# PIC32MK1024GPD100 device description
Architecture: MIPS; Family: PIC32MK; Series: PIC32MK
Registers are 32-bit, read-write, no defined reset value unless marked. A register's access mark holds for its fields unless they carry their own. Offsets are from the block's base; [hi:lo] are bit positions; 'fields as' and 'values as' point back to an identical list.

## SPI
Instances: SPI 0x1f827000 in periph_pb2_std
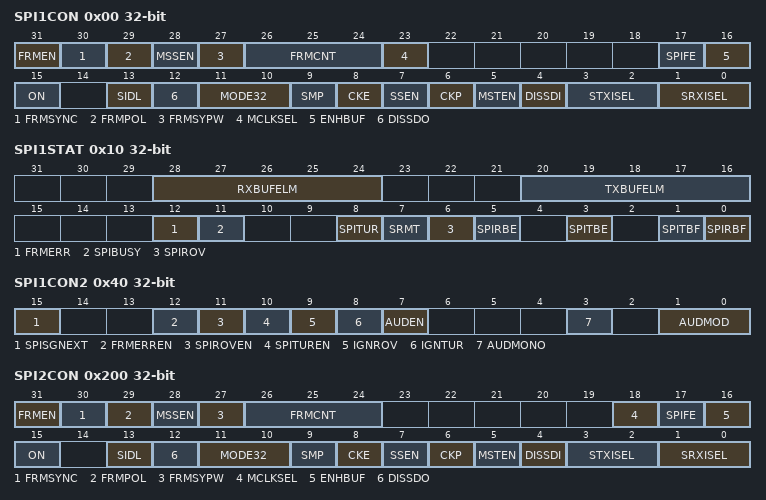
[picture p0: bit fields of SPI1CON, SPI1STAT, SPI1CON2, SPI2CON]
0x00 SPI1CON — SPI Control Register
  [31] FRMEN — Framed SPI Support bit
    1=Framed SPI support is enabled (SSx pin used as FSYNC input/output); 0=Framed SPI support is disabled
  [30] FRMSYNC — Frame Sync Pulse Direction Control on SSx pin bit
    1=Frame sync pulse input (Slave mode); 0=Frame sync pulse output (Master mode)
  [29] FRMPOL — Frame Sync Polarity bit
    1=Frame pulse is active-high; 0=Frame pulse is active-low
  [28] MSSEN — Master Mode Slave Select Enable bit
    1=Slave select SPI support enabled. The SS pin is automatically driven during transmission in Master mode. Polarity is determined by the FRMPOL bit.; 0=Slave select SPI support is disabled
  [27] FRMSYPW — Frame Sync Pulse Width bit
    1=Frame sync pulse is one character wide; 0=Frame sync pulse is one clock wide
  [26:24] FRMCNT — Frame Sync Pulse Counter bits. Controls the number of data characters transmitted per pulse. This bit is only valid in Framed mode.
    5=Generate a frame sync pulse on every 32 data characters; 4=Generate a frame sync pulse on every 16 data characters; 3=Generate a frame sync pulse on every 8 data characters; 2=Generate a frame sync pulse on every 4 data characters; 1=Generate a frame sync pulse on every 2 data characters; 0=Generate a frame sync pulse on every data character
  [23] MCLKSEL — Master Clock Enable bit
    1=REFCLKO1 is used by the Baud Rate Generator; 0=PBCLK2 is used by the Baud Rate Generator
  [17] SPIFE — Frame Sync Pulse Edge Select bit
    1=Frame synchronization pulse coincides with the first bit clock; 0=Frame synchronization pulse precedes the first bit clock
  [16] ENHBUF — Enhanced Buffer Enable bit
    1=Enhanced Buffer mode is enabled; 0=Enhanced Buffer mode is disabled
  [15] ON — SPI/I 2 S Module On bit
    1=SPI/I2S module is enabled; 0=SPI/I2S module is disabled
  [13] SIDL — Stop in Idle Mode bit
    1=Discontinue operation when CPU enters in Idle mode; 0=Continue operation in Idle mode
  [12] DISSDO — Disable SDOx pin bit
    1=SDOx pin is not used by the module. Pin is controlled by associated PORT register; 0=SDOx pin is controlled by the module
  [11:10] MODE32 — 32/16-Bit Communication Select bits
    3=SETTING1 ((AUDEN = 1) 24-bit Data, 32-bit FIFO, 32-bit Channel/64-bit Frame / (AUDEN = 0)32-bit); 2=SETTING2 ((AUDEN = 1) 32-bit Data, 32-bit FIFO, 32-bit Channel/64-bit Frame / (AUDEN = 0)32-bit); 1=SETTING3 ((AUDEN = 1) 16-bit Data, 16-bit FIFO, 32-bit Channel/64-bit Frame / (AUDEN = 0)16-bit); 0=SETTING4 ((AUDEN = 1) 16-bit Data, 16-bit FIFO, 16-bit Channel/32-bit Frame / (AUDEN = 0)8-bit)
  [9] SMP — SPI Data Input Sample Phase bit (master mode only)
    1=(Master mode) Input data sampled at end of data output time / (Slave mode) value is ignored; 0=(Master mode) Input data sampled at middle of data output time / (Slave mode) value is ignored
  [8] CKE — SPI Clock Edge Select bit
    1=Serial output data changes on transition from active clock state to Idle clock state (see CKP bit); 0=Serial output data changes on transition from Idle clock state to active clock state (see CKP bit)
  [7] SSEN — Slave Select Enable bit
    1=SSx pin used for Slave mode; 0=SSx pin not used for Slave mode
  [6] CKP — Clock Polarity Select bit
    1=Idle state for clock is a high level; active state is a low level; 0=Idle state for clock is a low level; active state is a high level
  [5] MSTEN — Master Mode Enable bit
    1=Master mode; 0=Slave mode
  [4] DISSDI — Disable SDI bit
    1=SDI pin is not used by the SPI module (pin is controlled by PORT function); 0=SDI pin is controlled by the SPI module
  [3:2] STXISEL — SPI Transmit Buffer Empty Interrupt Mode bits
    3=Interrupt is generated when the buffer is not full (has one or more empty elements); 2=Interrupt is generated when the buffer is empty by one-half or more; 1=Interrupt is generated when the buffer is completely empty; 0=Interrupt is generated when the last transfer is shifted out of SPISR and transmit operations are complete
  [1:0] SRXISEL — SPI Receive Buffer Full Interrupt Mode bits
    3=Interrupt is generated when the buffer is full; 2=Interrupt is generated when the buffer is full by one-half or more; 1=Interrupt is generated when the buffer is not empty; 0=Interrupt is generated when the last word in the receive buffer is read (i.e. buffer is empty)
0x10 SPI1STAT — SPI Status Register
  [28:24] RXBUFELM
  [20:16] TXBUFELM
  [12] FRMERR — SPI Frame Error status bit
    1=Frame error detected; 0=No Frame error detected
  [11] SPIBUSY — SPI Activity Status bit
    1=SPI peripheral is currently busy with some transactions; 0=SPI peripheral is currently idle
  [8] SPITUR — Transmit Under Run bit
    1=Transmit buffer has encountered an underrun condition; 0=Transmit buffer has no underrun condition
  [7] SRMT — Shift Register Empty bit
    1=When SPI module shift register is empty; 0=When SPI module shift register is not empty
  [6] SPIROV — Receive Overflow Flag bit
    1=A new data is completely received and discarded. The user software has not read the previous data in the SPIxBUF register.; 0=No overflow has occurred
  [5] SPIRBE — RX FIFO Empty bit (valid only when ENHBUF = 1)
    1=RX FIFO is empty (CRPTR = SWPTR); 0=RX FIFO is not empty (CRPTR ? SWPTR)
  [3] SPITBE — SPI Transmit Buffer Empty Status bit
    1=Transmit buffer; 0=Transmit buffer
  [1] SPITBF — SPI Transmit Buffer Full Status bit
    1=Transmit not yet started; 0=Transmit buffer is not full
  [0] SPIRBF — SPI Receive Buffer Full Status bit
    1=Receive buffer; 0=Receive buffer
0x20 SPI1BUF
0x30 SPI1BRG
  [12:0] SPI1BRG
0x40 SPI1CON2 — SPI Control Register 2
  [15] SPISGNEXT — Sign Extend Read Data from the RX FIFO bit
    1=Data from RX FIFO is sign extended; 0=Data from RX FIFO is not sign extened
  [12] FRMERREN — Enable Interrupt Events via FRMERR bit
    1=Frame Error overflow generates error events; 0=Frame Error does not generate error events
  [11] SPIROVEN — Enable Interrupt Events via SPIROV bit
    1=Receive overflow generates error events; 0=Receive overflow does not generate error events
  [10] SPITUREN — Enable Interrupt Events via SPITUR bit
    1=Transmit Underrun Generates Error Events; 0=Transmit Underrun Does Not Generates Error Events
  [9] IGNROV — Ignore Receive Overflow bit
    1=A ROV is not a critical error; during ROV data in the fifo is not overwritten by receive data; 0=A ROV is a critical error which stop SPI operation
  [8] IGNTUR — Ignore Transmit Underrun bit
    1=A TUR is not a critical error and zeros are transmitted until the SPIxTXB is not empty; 0=A TUR is a critical error which stop SPI operation
  [7] AUDEN — Enable Audio CODEC Support bit
    1=Audio protocol enabled; 0=Audio protocol disabled
  [3] AUDMONO — Transmit Audio Data Format bit
    1=Audio data is mono (Each data word is transmitted on both left and right channels); 0=Audio data is stereo
  [1:0] AUDMOD — Audio Protocol Mode bit
    3=PCM/DSP mode; 2=Right Justified mode; 1=Left Justified mode; 0=I2S mode
0x200 SPI2CON — SPI Control Register
  [31] FRMEN — Framed SPI Support bit
    values as SPI1CON.FRMEN
  [30] FRMSYNC — Frame Sync Pulse Direction Control on SSx pin bit
    values as SPI1CON.FRMSYNC
  [29] FRMPOL — Frame Sync Polarity bit
    1=Frame pulse is active-high; 0=Frame pulse is active-low
  [28] MSSEN — Master Mode Slave Select Enable bit
    values as SPI1CON.MSSEN
  [27] FRMSYPW — Frame Sync Pulse Width bit
    values as SPI1CON.FRMSYPW
  [26:24] FRMCNT — Frame Sync Pulse Counter bits. Controls the number of data characters transmitted per pulse. This bit is only valid in Framed mode.
    values as SPI1CON.FRMCNT
  [18] MCLKSEL — Master Clock Enable bit
    values as SPI1CON.MCLKSEL
  [17] SPIFE — Frame Sync Pulse Edge Select bit
    values as SPI1CON.SPIFE
  [16] ENHBUF — Enhanced Buffer Enable bit
    values as SPI1CON.ENHBUF
  [15] ON — SPI/I 2 S Module On bit
    1=SPI/I2S module is enabled; 0=SPI/I2S module is disabled
  [13] SIDL — Stop in Idle Mode bit
    values as SPI1CON.SIDL
  [12] DISSDO — Disable SDOx pin bit
    values as SPI1CON.DISSDO
  [11:10] MODE32 — 32/16-Bit Communication Select bits
    values as SPI1CON.MODE32
  [9] SMP — SPI Data Input Sample Phase bit (master mode only)
    values as SPI1CON.SMP
  [8] CKE — SPI Clock Edge Select bit
    values as SPI1CON.CKE
  [7] SSEN — Slave Select Enable bit
    values as SPI1CON.SSEN
  [6] CKP — Clock Polarity Select bit
    values as SPI1CON.CKP
  [5] MSTEN — Master Mode Enable bit
    1=Master mode; 0=Slave mode
  [4] DISSDI — Disable SDI bit
    values as SPI1CON.DISSDI
  [3:2] STXISEL — SPI Transmit Buffer Empty Interrupt Mode bits
    values as SPI1CON.STXISEL
  [1:0] SRXISEL — SPI Receive Buffer Full Interrupt Mode bits
    values as SPI1CON.SRXISEL
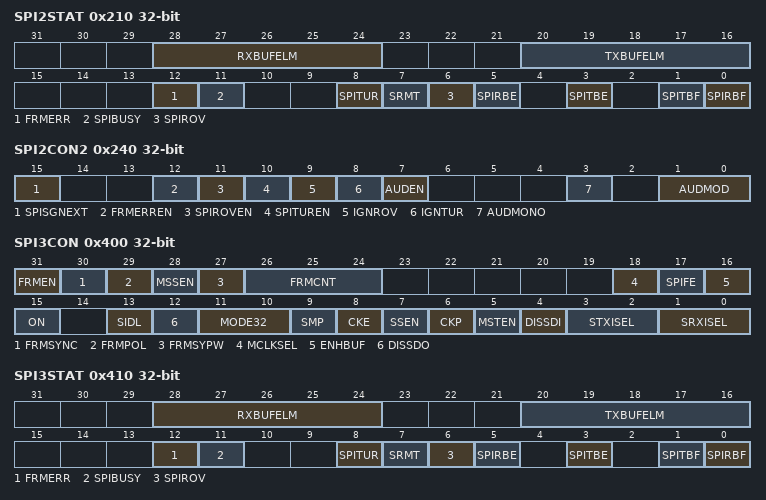
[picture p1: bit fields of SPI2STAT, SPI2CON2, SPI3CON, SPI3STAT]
0x210 SPI2STAT — SPI Status Register
  fields as SPI1STAT
0x220 SPI2BUF
0x230 SPI2BRG
  [12:0] SPI2BRG
0x240 SPI2CON2 — SPI Control Register 2
  fields as SPI1CON2
0x400 SPI3CON — SPI Control Register
  [31] FRMEN — Framed SPI Support bit
    values as SPI1CON.FRMEN
  [30] FRMSYNC — Frame Sync Pulse Direction Control on SSx pin bit
    values as SPI1CON.FRMSYNC
  [29] FRMPOL — Frame Sync Polarity bit
    1=Frame pulse is active-high; 0=Frame pulse is active-low
  [28] MSSEN — Master Mode Slave Select Enable bit
    values as SPI1CON.MSSEN
  [27] FRMSYPW — Frame Sync Pulse Width bit
    values as SPI1CON.FRMSYPW
  [26:24] FRMCNT — Frame Sync Pulse Counter bits. Controls the number of data characters transmitted per pulse. This bit is only valid in Framed mode.
    values as SPI1CON.FRMCNT
  [18] MCLKSEL — Master Clock Enable bit
    1=REFCLKO1 is used by the Baud Rate Generator; 0=PBCLK3 is used by the Baud Rate Generator
  [17] SPIFE — Frame Sync Pulse Edge Select bit
    values as SPI1CON.SPIFE
  [16] ENHBUF — Enhanced Buffer Enable bit
    values as SPI1CON.ENHBUF
  [15] ON — SPI/I 2 S Module On bit
    1=SPI/I2S module is enabled; 0=SPI/I2S module is disabled
  [13] SIDL — Stop in Idle Mode bit
    values as SPI1CON.SIDL
  [12] DISSDO — Disable SDOx pin bit
    values as SPI1CON.DISSDO
  [11:10] MODE32 — 32/16-Bit Communication Select bits
    values as SPI1CON.MODE32
  [9] SMP — SPI Data Input Sample Phase bit (master mode only)
    values as SPI1CON.SMP
  [8] CKE — SPI Clock Edge Select bit
    values as SPI1CON.CKE
  [7] SSEN — Slave Select Enable bit
    values as SPI1CON.SSEN
  [6] CKP — Clock Polarity Select bit
    values as SPI1CON.CKP
  [5] MSTEN — Master Mode Enable bit
    1=Master mode; 0=Slave mode
  [4] DISSDI — Disable SDI bit
    values as SPI1CON.DISSDI
  [3:2] STXISEL — SPI Transmit Buffer Empty Interrupt Mode bits
    values as SPI1CON.STXISEL
  [1:0] SRXISEL — SPI Receive Buffer Full Interrupt Mode bits
    values as SPI1CON.SRXISEL
0x410 SPI3STAT — SPI Status Register
  fields as SPI1STAT
0x420 SPI3BUF
0x430 SPI3BRG
  [12:0] SPI3BRG
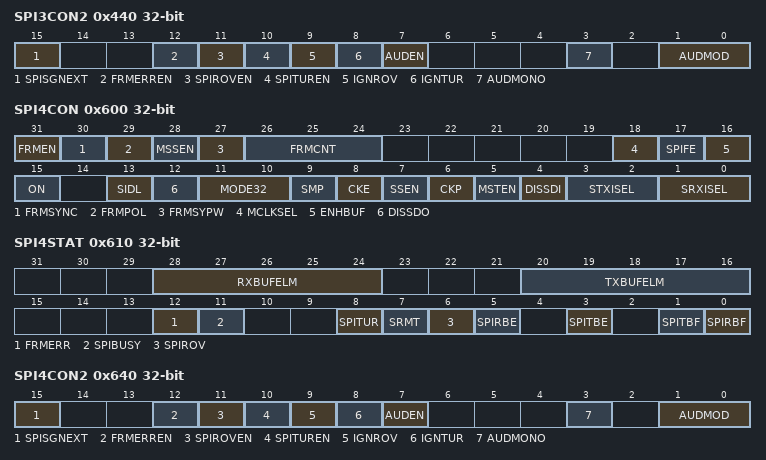
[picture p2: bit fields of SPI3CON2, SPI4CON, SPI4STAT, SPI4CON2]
0x440 SPI3CON2 — SPI Control Register 2
  fields as SPI1CON2
0x600 SPI4CON — SPI Control Register
  fields as SPI3CON
0x610 SPI4STAT — SPI Status Register
  fields as SPI1STAT
0x620 SPI4BUF
0x630 SPI4BRG
  [12:0] SPI4BRG
0x640 SPI4CON2 — SPI Control Register 2
  fields as SPI1CON2
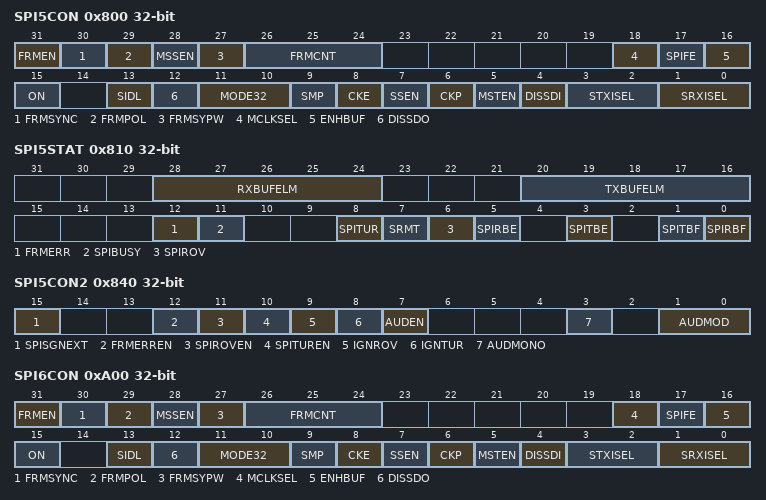
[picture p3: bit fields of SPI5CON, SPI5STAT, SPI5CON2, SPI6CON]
0x800 SPI5CON — SPI Control Register
  fields as SPI3CON
0x810 SPI5STAT — SPI Status Register
  fields as SPI1STAT
0x820 SPI5BUF
0x830 SPI5BRG
  [12:0] SPI5BRG
0x840 SPI5CON2 — SPI Control Register 2
  fields as SPI1CON2
0xA00 SPI6CON — SPI Control Register
  fields as SPI3CON
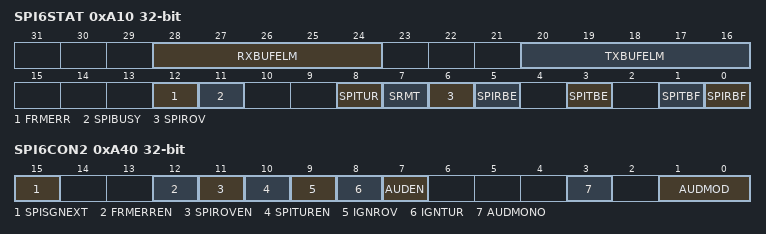
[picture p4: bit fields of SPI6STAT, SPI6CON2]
0xA10 SPI6STAT — SPI Status Register
  fields as SPI1STAT
0xA20 SPI6BUF
0xA30 SPI6BRG
  [12:0] SPI6BRG
0xA40 SPI6CON2 — SPI Control Register 2
  fields as SPI1CON2

## Notices in the file
Copyright (c) 2017 Microchip Technology Inc.
SPDX-License-Identifier: Apache-2.0
Licensed under the Apache License, Version 2.0 (the "License");
you may not use this file except in compliance with the License.
You may obtain a copy of the License at
http://www.apache.org/licenses/LICENSE-2.0
Unless required by applicable law or agreed to in writing, software
distributed under the License is distributed on an "AS IS" BASIS,
WITHOUT WARRANTIES OR CONDITIONS OF ANY KIND, either express or implied.
See the License for the specific language governing permissions and
limitations under the License.
